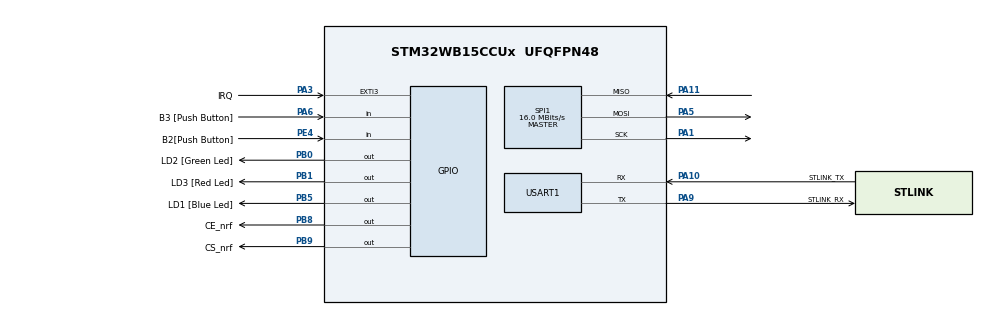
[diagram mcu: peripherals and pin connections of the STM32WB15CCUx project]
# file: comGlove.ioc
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Mcu.Family=STM32WB
Mcu.Name=STM32WB15CCUx
Mcu.Package=UFQFPN48
NVIC.EXTI3_IRQn=true\:0\:0\:false\:false\:true\:true\:true\:true
NVIC.PriorityGroup=NVIC_PRIORITYGROUP_4
OSC_IN.Mode=HSE-External-Oscillator
OSC_IN.Signal=RCC_OSC_IN
OSC_OUT.Mode=HSE-External-Oscillator
OSC_OUT.Signal=RCC_OSC_OUT
PA0.GPIO_Label=B1 [push Button]
PA0.Mode=SYS_WakeUp0
PA0.Signal=SYS_WKUP1
PA1.Mode=Full_Duplex_Master
PA1.Signal=SPI1_SCK
PA10.GPIO_Label=STLINK_TX
PA10.Mode=Asynchronous
PA10.Signal=USART1_RX
PA11.Mode=Full_Duplex_Master
PA11.Signal=SPI1_MISO
PA13.GPIO_Label=JTMS
PA13.Mode=Serial_Wire
PA13.Signal=SYS_JTMS-SWDIO
PA14.GPIO_Label=JTCK
PA14.Mode=Serial_Wire
PA14.Signal=SYS_JTCK-SWCLK
PA3.GPIO_Label=IRQ
PA3.Signal=GPXTI3
PA5.Mode=Full_Duplex_Master
PA5.Signal=SPI1_MOSI
PA6.GPIO_Label=B3 [Push Button]
PA6.Signal=GPIO_Input
PA9.GPIO_Label=STLINK_RX
PA9.Mode=Asynchronous
PA9.Signal=USART1_TX
PB0.GPIO_Label=LD2 [Green Led]
PB0.Signal=GPIO_Output
PB1.GPIO_Label=LD3 [Red Led]
PB1.Signal=GPIO_Output
PB3.GPIO_Label=JTDO
PB3.Signal=SYS_JTDO-SWO
PB5.GPIO_Label=LD1 [Blue Led]
PB5.Signal=GPIO_Output
PB8.GPIO_Label=CE_nrf
PB8.Signal=GPIO_Output
PB9.GPIO_Label=CS_nrf
PB9.Signal=GPIO_Output
PC14-OSC32_IN.Mode=LSE-External-Oscillator
PC14-OSC32_IN.Signal=RCC_OSC32_IN
PC15-OSC32_OUT.Mode=LSE-External-Oscillator
PC15-OSC32_OUT.Signal=RCC_OSC32_OUT
PE4.GPIO_Label=B2[Push Button]
PE4.Signal=GPIO_Input
ProjectManager.HeapSize=0x200
ProjectManager.StackSize=0x400
ProjectManager.TargetToolchain=STM32CubeIDE
RCC.AHBFreq_Value=32000000
RCC.APB1Freq_Value=32000000
RCC.APB1TimFreq_Value=32000000
RCC.APB2Freq_Value=32000000
RCC.APB2TimFreq_Value=32000000
RCC.APB3Freq_Value=16000000
RCC.CortexFreq_Value=32000000
RCC.HCLKFreq_Value=32000000
RCC.HSE_VALUE=32000000
RCC.HSI_VALUE=16000000
RCC.LSE_Drive_Capability=RCC_LSEDRIVE_LOW
RCC.MSIClockRange=RCC_MSIRANGE_10
RCC.SYSCLKFreq_VALUE=32000000
RCC.VCOOutputFreq_Value=256000000
RF1.Mode=RF1_Activate
RF1.Signal=RF_RF1
SPI1.CalculateBaudRate=16.0 MBits/s
SPI1.Direction=SPI_DIRECTION_2LINES
SPI1.Mode=SPI_MODE_MASTER
SPI1.VirtualType=VM_MASTER
USART1.VirtualMode-Asynchronous=VM_ASYNC
board=NUCLEO-WB15CC

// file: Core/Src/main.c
/* USER CODE BEGIN Header */
/**
  ******************************************************************************
  * @file           : main.c
  * @brief          : Main program body
  ******************************************************************************
  * @attention
  *
  * Copyright (c) 2023 STMicroelectronics.
  * All rights reserved.
  *
  * This software is licensed under terms that can be found in the LICENSE file
  * in the root directory of this software component.
  * If no LICENSE file comes with this software, it is provided AS-IS.
  *
  ******************************************************************************
  */
/* USER CODE END Header */
#include "main.h"
#include "rf.h"
#include "spi.h"
#include "usart.h"
#include "gpio.h"
#include "demo_transmitter.h"
#include "demo_receiver.h"

/* USER CODE BEGIN Includes */
#include "nrf24l01p.h"
/* USER CODE END Includes */

/* USER CODE BEGIN PM */
#define TRANSMITTER
/* USER CODE END PM */

/* USER CODE BEGIN PV */
//uint8_t tx_data[NRF24L01P_PAYLOAD_LENGTH] = {0, 1, 2, 3, 4, 5, 6, 7};
/* USER CODE END PV */

void SystemClock_Config(void);
void PeriphCommonClock_Config(void);
/* USER CODE BEGIN PFP */
// for rx interrupt

/* USER CODE END PFP */

/* USER CODE BEGIN 0 */
int __io_putchar(int ch) {
HAL_UART_Transmit(&huart1, (uint8_t *)&ch, 1, HAL_MAX_DELAY); return ch;
}
/* USER CODE END 0 */

int main(void)
{

  /* MCU Configuration--------------------------------------------------------*/

  /* Reset of all peripherals, Initializes the Flash interface and the Systick. */
  HAL_Init();

  /* Configure the system clock */
  SystemClock_Config();

/* Configure the peripherals common clocks */
  PeriphCommonClock_Config();

  /* Initialize all configured peripherals */
  MX_GPIO_Init();
  MX_RF_Init();
  MX_SPI1_Init();
  MX_USART1_UART_Init();

  /* Infinite loop */
  /* USER CODE BEGIN WHILE */
 /* while (1)
  {
	  HAL_GPIO_WritePin(GPIOB,GPIO_PIN_0,GPIO_PIN_SET);
	  printf("Helloooo led \r\n");
	  HAL_Delay(100);
	  HAL_GPIO_WritePin(GPIOB,GPIO_PIN_0,GPIO_PIN_RESET);
	  HAL_Delay(100);

 }*/

    /* USER CODE END WHILE */

    /* USER CODE BEGIN 3 */
  //transmitter();
  receiver();
  /* USER CODE END 3 */
}

void SystemClock_Config(void)
{
  RCC_OscInitTypeDef RCC_OscInitStruct = {0};
  RCC_ClkInitTypeDef RCC_ClkInitStruct = {0};

  /** Configure LSE Drive Capability
  */
  HAL_PWR_EnableBkUpAccess();
  __HAL_RCC_LSEDRIVE_CONFIG(RCC_LSEDRIVE_LOW);

  /** Initializes the RCC Oscillators according to the specified parameters
  * in the RCC_OscInitTypeDef structure.
  */
  RCC_OscInitStruct.OscillatorType = RCC_OSCILLATORTYPE_HSI|RCC_OSCILLATORTYPE_LSI1
                              |RCC_OSCILLATORTYPE_HSE|RCC_OSCILLATORTYPE_LSE
                              |RCC_OSCILLATORTYPE_MSI;
  RCC_OscInitStruct.HSEState = RCC_HSE_ON;
  RCC_OscInitStruct.LSEState = RCC_LSE_ON;
  RCC_OscInitStruct.HSIState = RCC_HSI_ON;
  RCC_OscInitStruct.MSIState = RCC_MSI_ON;
  RCC_OscInitStruct.HSICalibrationValue = RCC_HSICALIBRATION_DEFAULT;
  RCC_OscInitStruct.MSICalibrationValue = RCC_MSICALIBRATION_DEFAULT;
  RCC_OscInitStruct.MSIClockRange = RCC_MSIRANGE_10;
  RCC_OscInitStruct.LSIState = RCC_LSI_ON;
  RCC_OscInitStruct.PLL.PLLState = RCC_PLL_NONE;
  if (HAL_RCC_OscConfig(&RCC_OscInitStruct) != HAL_OK)
  {
    Error_Handler();
  }

  /** Configure the SYSCLKSource, HCLK, PCLK1 and PCLK2 clocks dividers
  */
  RCC_ClkInitStruct.ClockType = RCC_CLOCKTYPE_HCLK4|RCC_CLOCKTYPE_HCLK2
                              |RCC_CLOCKTYPE_HCLK|RCC_CLOCKTYPE_SYSCLK
                              |RCC_CLOCKTYPE_PCLK1|RCC_CLOCKTYPE_PCLK2;
  RCC_ClkInitStruct.SYSCLKSource = RCC_SYSCLKSOURCE_MSI;
  RCC_ClkInitStruct.AHBCLKDivider = RCC_SYSCLK_DIV1;
  RCC_ClkInitStruct.APB1CLKDivider = RCC_HCLK_DIV1;
  RCC_ClkInitStruct.APB2CLKDivider = RCC_HCLK_DIV1;
  RCC_ClkInitStruct.AHBCLK2Divider = RCC_SYSCLK_DIV1;
  RCC_ClkInitStruct.AHBCLK4Divider = RCC_SYSCLK_DIV1;

  if (HAL_RCC_ClockConfig(&RCC_ClkInitStruct, FLASH_LATENCY_1) != HAL_OK)
  {
    Error_Handler();
  }

  /** Enable MSI Auto calibration
  */
  HAL_RCCEx_EnableMSIPLLMode();
}

void PeriphCommonClock_Config(void)
{
  RCC_PeriphCLKInitTypeDef PeriphClkInitStruct = {0};

  /** Initializes the peripherals clock
  */
  PeriphClkInitStruct.PeriphClockSelection = RCC_PERIPHCLK_SMPS|RCC_PERIPHCLK_RFWAKEUP;
  PeriphClkInitStruct.RFWakeUpClockSelection = RCC_RFWKPCLKSOURCE_LSI;
  PeriphClkInitStruct.SmpsClockSelection = RCC_SMPSCLKSOURCE_HSI;
  PeriphClkInitStruct.SmpsDivSelection = RCC_SMPSCLKDIV_RANGE1;

  if (HAL_RCCEx_PeriphCLKConfig(&PeriphClkInitStruct) != HAL_OK)
  {
    Error_Handler();
  }
}

void Error_Handler(void)
{
  __disable_irq();
  while (1)
  {
  }
}
